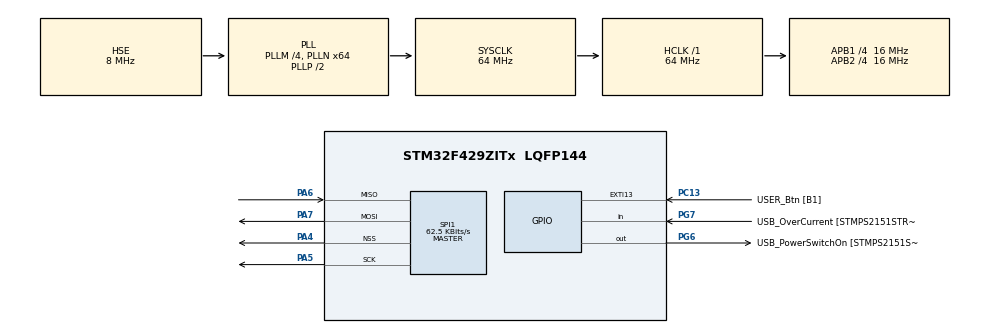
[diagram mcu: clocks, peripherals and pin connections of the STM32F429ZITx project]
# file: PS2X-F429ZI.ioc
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Mcu.Family=STM32F4
PA6.Mode=Full_Duplex_Master
RCC.CortexFreq_Value=64000000
PG6.Signal=GPIO_Output
SPI1.VirtualType=VM_MASTER
PA14.GPIO_Label=TCK
PG6.GPIO_Label=USB_PowerSwitchOn [STMPS2151STR_EN]
RCC.SYSCLKSourceVirtual=RCC_SYSCLKSOURCE_PLLCLK
PC14/OSC32_IN.Mode=LSE-External-Oscillator
PC13.GPIO_Label=USER_Btn [B1]
RCC.SYSCLKSource=RCC_SYSCLKSOURCE_PLLCLK
ProjectManager.StackSize=0x400
SPI1.CLKPolarity=SPI_POLARITY_HIGH
PA4.Mode=NSS_Signal_Hard_Output
SPI1.Direction=SPI_DIRECTION_2LINES
PH0/OSC_IN.Mode=HSE-External-Clock-Source
RCC.HCLKFreq_Value=64000000
RCC.APB2TimFreq_Value=32000000
PH1/OSC_OUT.Signal=RCC_OSC_OUT
SPI1.CalculateBaudRate=62.5 KBits/s
RCC.AHBFreq_Value=64000000
RCC.HSE_VALUE=8000000
RCC.PLLMUL=RCC_PLL_MUL9
PA14.Mode=Serial_Wire
SPI1.VirtualNSS=VM_NSSHARD
SPI1.FirstBit=SPI_FIRSTBIT_LSB
PH1/OSC_OUT.Mode=HSE-External-Clock-Source
Mcu.Package=LQFP144
PA6.Signal=SPI1_MISO
PC14/OSC32_IN.Signal=RCC_OSC32_IN
RCC.APB2CLKDivider=RCC_HCLK_DIV4
RCC.APB1TimFreq_Value=32000000
SPI1.BaudRatePrescaler=SPI_BAUDRATEPRESCALER_256
PA5.Mode=Full_Duplex_Master
RCC.PLLSourceVirtual=RCC_PLLSOURCE_HSE
PA7.Mode=Full_Duplex_Master
PG7.Signal=GPIO_Input
PC13.Signal=GPXTI13
SPI1.CLKPhase=SPI_PHASE_2EDGE
RCC.APB1CLKDivider=RCC_HCLK_DIV4
PA13.Signal=SYS_JTMS-SWDIO
ProjectManager.TargetToolchain=STM32CubeIDE
RCC.USBFreq_Value=48000000
PA5.Signal=SPI1_SCK
board=NUCLEO-F429ZI
RCC.VCOOutputFreq_Value=128000000
PH0/OSC_IN.Signal=RCC_OSC_IN
RCC.APB2Freq_Value=16000000
RCC.PRESCALERUSB=RCC_USBCLKSOURCE_PLL_DIV1_5
SPI1.Mode=SPI_MODE_MASTER
PG7.GPIO_Label=USB_OverCurrent [STMPS2151STR_FAULT]
PA13.Mode=Serial_Wire
Mcu.Name=STM32F429ZITx
PA13.GPIO_Label=TMS
RCC.48MHZClocksFreq_Value=18285714.285714287
PA4.Signal=SPI1_NSS
RCC.SYSCLKFreq_VALUE=64000000
PC15/OSC32_OUT.Mode=LSE-External-Oscillator
PA14.Signal=SYS_JTCK-SWCLK
ProjectManager.HeapSize=0x200
RCC.HSI_VALUE=16000000
PH0/OSC_IN.GPIO_Label=MCO [STM32F103CBT6_PA8]
RCC.PLLQ=7
NVIC.PriorityGroup=NVIC_PRIORITYGROUP_4
RCC.PLLM=4
RCC.PLLN=64
PC15/OSC32_OUT.Signal=RCC_OSC32_OUT
RCC.APB1Freq_Value=16000000
PA7.Signal=SPI1_MOSI

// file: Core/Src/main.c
/* USER CODE BEGIN Header */
/**
  ******************************************************************************
  * @file           : main.c
  * @brief          : Main program body
  ******************************************************************************
  * @attention
  *
  * <h2><center>&copy; Copyright (c) 2021 STMicroelectronics.
  * All rights reserved.</center></h2>
  *
  * This software component is licensed by ST under BSD 3-Clause license,
  * the "License"; You may not use this file except in compliance with the
  * License. You may obtain a copy of the License at:
  *                        opensource.org/licenses/BSD-3-Clause
  *
  ******************************************************************************
  */
/* USER CODE END Header */
#include "main.h"

SPI_HandleTypeDef hspi1;

/* USER CODE BEGIN PV */
uint8_t PSX_RX[8];
uint8_t PSX_TX[2] = {
		0x01, 0x42
};
/* USER CODE END PV */

void SystemClock_Config(void);
static void MX_GPIO_Init(void);
static void MX_SPI1_Init(void);

int main(void)
{

  /* MCU Configuration--------------------------------------------------------*/

  /* Reset of all peripherals, Initializes the Flash interface and the Systick. */
  HAL_Init();

  /* Configure the system clock */
  SystemClock_Config();

  /* Initialize all configured peripherals */
  MX_GPIO_Init();
  MX_SPI1_Init();

  /* Infinite loop */
  while (1)
  {
	  GPIOA->ODR &= ~(1 << 4);
	  HAL_SPI_TransmitReceive(&hspi1, PSX_TX, PSX_RX, 8, 10);
	  GPIOA->ODR |= (1 << 4);

	  /* HOW TO USE
	   * To see the data being received by the SPI, use live expression feature on debugging option.
	   * the data that received is 8bit LSB.
	   * For more information about the protocol, visit this link :
	   * https://store.curiousinventor.com/guides/PS2
	   */

  }
}

void SystemClock_Config(void)
{
  RCC_OscInitTypeDef RCC_OscInitStruct = {0};
  RCC_ClkInitTypeDef RCC_ClkInitStruct = {0};

  /** Configure the main internal regulator output voltage
  */
  __HAL_RCC_PWR_CLK_ENABLE();
  __HAL_PWR_VOLTAGESCALING_CONFIG(PWR_REGULATOR_VOLTAGE_SCALE3);
  /** Initializes the RCC Oscillators according to the specified parameters
  * in the RCC_OscInitTypeDef structure.
  */
  RCC_OscInitStruct.OscillatorType = RCC_OSCILLATORTYPE_HSE;
  RCC_OscInitStruct.HSEState = RCC_HSE_BYPASS;
  RCC_OscInitStruct.PLL.PLLState = RCC_PLL_ON;
  RCC_OscInitStruct.PLL.PLLSource = RCC_PLLSOURCE_HSE;
  RCC_OscInitStruct.PLL.PLLM = 4;
  RCC_OscInitStruct.PLL.PLLN = 64;
  RCC_OscInitStruct.PLL.PLLP = RCC_PLLP_DIV2;
  RCC_OscInitStruct.PLL.PLLQ = 7;
  if (HAL_RCC_OscConfig(&RCC_OscInitStruct) != HAL_OK)
  {
    Error_Handler();
  }
  /** Initializes the CPU, AHB and APB buses clocks
  */
  RCC_ClkInitStruct.ClockType = RCC_CLOCKTYPE_HCLK|RCC_CLOCKTYPE_SYSCLK
                              |RCC_CLOCKTYPE_PCLK1|RCC_CLOCKTYPE_PCLK2;
  RCC_ClkInitStruct.SYSCLKSource = RCC_SYSCLKSOURCE_PLLCLK;
  RCC_ClkInitStruct.AHBCLKDivider = RCC_SYSCLK_DIV1;
  RCC_ClkInitStruct.APB1CLKDivider = RCC_HCLK_DIV4;
  RCC_ClkInitStruct.APB2CLKDivider = RCC_HCLK_DIV4;

  if (HAL_RCC_ClockConfig(&RCC_ClkInitStruct, FLASH_LATENCY_2) != HAL_OK)
  {
    Error_Handler();
  }
}

static void MX_SPI1_Init(void)
{

  /* SPI1 parameter configuration*/
  hspi1.Instance = SPI1;
  hspi1.Init.Mode = SPI_MODE_MASTER;
  hspi1.Init.Direction = SPI_DIRECTION_2LINES;
  hspi1.Init.DataSize = SPI_DATASIZE_8BIT;
  hspi1.Init.CLKPolarity = SPI_POLARITY_HIGH;
  hspi1.Init.CLKPhase = SPI_PHASE_2EDGE;
  hspi1.Init.NSS = SPI_NSS_HARD_OUTPUT;
  hspi1.Init.BaudRatePrescaler = SPI_BAUDRATEPRESCALER_256;
  hspi1.Init.FirstBit = SPI_FIRSTBIT_LSB;
  hspi1.Init.TIMode = SPI_TIMODE_DISABLE;
  hspi1.Init.CRCCalculation = SPI_CRCCALCULATION_DISABLE;
  hspi1.Init.CRCPolynomial = 10;
  if (HAL_SPI_Init(&hspi1) != HAL_OK)
  {
    Error_Handler();
  }

}

static void MX_GPIO_Init(void)
{
  GPIO_InitTypeDef GPIO_InitStruct = {0};

  /* GPIO Ports Clock Enable */
  __HAL_RCC_GPIOC_CLK_ENABLE();
  __HAL_RCC_GPIOH_CLK_ENABLE();
  __HAL_RCC_GPIOA_CLK_ENABLE();
  __HAL_RCC_GPIOG_CLK_ENABLE();

  /*Configure GPIO pin Output Level */
  HAL_GPIO_WritePin(USB_PowerSwitchOn_GPIO_Port, USB_PowerSwitchOn_Pin, GPIO_PIN_RESET);

  /*Configure GPIO pin : USER_Btn_Pin */
  GPIO_InitStruct.Pin = USER_Btn_Pin;
  GPIO_InitStruct.Mode = GPIO_MODE_IT_RISING;
  GPIO_InitStruct.Pull = GPIO_NOPULL;
  HAL_GPIO_Init(USER_Btn_GPIO_Port, &GPIO_InitStruct);

  /*Configure GPIO pin : USB_PowerSwitchOn_Pin */
  GPIO_InitStruct.Pin = USB_PowerSwitchOn_Pin;
  GPIO_InitStruct.Mode = GPIO_MODE_OUTPUT_PP;
  GPIO_InitStruct.Pull = GPIO_NOPULL;
  GPIO_InitStruct.Speed = GPIO_SPEED_FREQ_LOW;
  HAL_GPIO_Init(USB_PowerSwitchOn_GPIO_Port, &GPIO_InitStruct);

  /*Configure GPIO pin : USB_OverCurrent_Pin */
  GPIO_InitStruct.Pin = USB_OverCurrent_Pin;
  GPIO_InitStruct.Mode = GPIO_MODE_INPUT;
  GPIO_InitStruct.Pull = GPIO_NOPULL;
  HAL_GPIO_Init(USB_OverCurrent_GPIO_Port, &GPIO_InitStruct);

}

void Error_Handler(void)
{
  __disable_irq();
  while (1)
  {
  }
}

/************************ (C) COPYRIGHT STMicroelectronics *****END OF FILE****/
